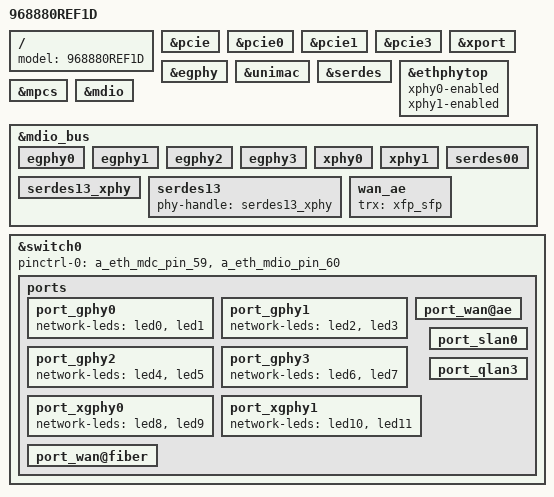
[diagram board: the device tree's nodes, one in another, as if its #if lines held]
#include "inc/968880REF1D.dtsi"

/ {
    model = "968880REF1D";
};

#if defined(CONFIG_BCM_PCIE_HCD) || defined(CONFIG_BCM_PCIE_HCD_MODULE)
&pcie {
      status = "okay";
};

&pcie0 {
      status = "okay";
};

&pcie1 {
      status = "okay";
};

&pcie3 {
      status = "okay";
};
#endif // defined(CONFIG_BCM_PCIE_HCD) || defined(CONFIG_BCM_PCIE_HCD_MODULE)

&xport {
    status = "okay";
};

&egphy {
    status = "okay";
};

&unimac {
    status = "okay";
};

&serdes {
    status = "okay";
};

&ethphytop {
    xphy0-enabled;
    xphy1-enabled;
    status = "okay";
};

&mpcs {
    status = "okay";
};

&mdio {
    status = "okay";
};

&mdio_bus {
    egphy0 {
        status = "okay";
    };
    egphy1 {
        status = "okay";
    };
    egphy2 {
        status = "okay";
    };
    egphy3 {
        status = "okay";
    };
    xphy0 {
        status = "okay";
    };
    xphy1 {
        status = "okay";
    };
    serdes00 {
        status = "okay";
    };
    serdes13_xphy {
        status = "okay";
    };
    serdes13 {
        phy-handle = <&serdes13_xphy>;
        status = "okay";
    };
    wan_ae {
        trx = <&xfp_sfp>;
        status = "okay";
    };
};

&switch0 {
    pinctrl-names = "default";
    pinctrl-0 = <&a_eth_mdc_pin_59 &a_eth_mdio_pin_60>;

    ports {
        port_gphy0 {
            network-leds = <&led0 &led1>;
            status = "okay";
        };
        port_gphy1 {
            network-leds = <&led2 &led3>;
            status = "okay";
        };
        port_gphy2 {
            network-leds = <&led4 &led5>;
            status = "okay";
        };
        port_gphy3 {
            network-leds = <&led6 &led7>;
            status = "okay";
        };
        port_xgphy0 {
            network-leds = <&led8 &led9>;
            status = "okay";
        };
        port_wan@ae {
            status = "okay";
        };
        port_xgphy1 {
            network-leds = <&led10 &led11>;
            status = "okay";
        };
        port_slan0 {
            status = "okay";
        };
        port_qlan3 {
            status = "okay";
        };
        port_wan@fiber {
            status = "okay";
        };
    };
};
